# MM32F3270 register map
File version: 3.01
CPU: CM3 r2p1, selectable endian, MPU, no FPU, 3 interrupt priority bits
Registers are 32-bit, read-write, reset 0x0 unless marked. A register's access mark holds for its fields unless they carry their own. Offsets are from the block's base; [hi:lo] are bit positions; {n}, {i} and the like mark numbered series.

## Ethernet_MAC — Ethernet: media access control (MAC)
Base 0x40028000
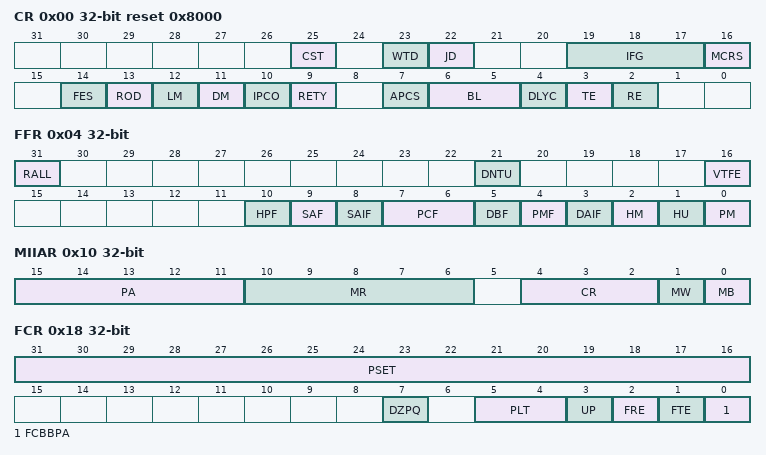
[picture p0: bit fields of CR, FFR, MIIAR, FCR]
0x00 CR reset 0x8000 — Ethernet MAC configuration register
  [25] CST — CRC stripping for Type frames
  [23] WTD — Watchdog Disable
  [22] JD — Jabber Disable
  [19:17] IFG — Inter Frame Gap
  [16] MCRS — Carrier sense disable
  [14] FES — Fast Ethernet Speed
  [13] ROD — Receive Own Disable
  [12] LM — Loopback Mode
  [11] DM — Duplex Mode
  [10] IPCO — IPv4 Checksum Offload
  [9] RETY — Retry disable
  [7] APCS — Automatic pad/CRC stripping
  [6:5] BL — Back-off limit
  [4] DLYC — Deferral check
  [3] TE — Transmitter enable
  [2] RE — Receiver enable
0x04 FFR — Ethernet MAC frame filter register
  [31] RALL — Receive All
  [21] DNTU — The MAC receiver discards all IP packets without TCP or UDP fields
  [16] VTFE — VLAN Filter Enable
  [10] HPF — Hash or Perfect Filter
  [9] SAF — Source Address Filter
  [8] SAIF — Source Address Inverse Filtering
  [7:6] PCF — Pass Control Frames
  [5] DBF — Broadcast Frames Disable
  [4] PMF — Pass All Multicast
  [3] DAIF — Destination address inverse filter-ing
  [2] HM — Hash Multicast
  [1] HU — Hash Unicast
  [0] PM — Promiscuous Mode
0x08 HTHR — Ethernet MAC hash table high register
  [31:0] HTABH — Hash Table High
0x0C HTLR — Ethernet MAC hash table low register
  [31:0] HTABL — Hash Table Low
0x10 MIIAR — Ethernet MAC MII address register
  [15:11] PA — PHY Address
  [10:6] MR — MII Register
  [4:2] CR — Clock Range
  [1] MW — MII Write
  [0] MB write-1-clears — MII Busy
0x14 MIIDR — Ethernet MAC MII data register
  [15:0] MD — MII data
0x18 FCR — Ethernet MAC flow control register
  [31:16] PSET — Pause time
  [7] DZPQ — When the flow control signal is valid, it is forbidden to generate a zero-slice pause control frame
  [5:4] PLT — Pause Low Threshold
  [3] UP — Unicast Pause Frame Detect
  [2] FRE — Receive Flow Control Enable
  [1] FTE — Transmit Flow Control Enable
  [0] FCBBPA — Flow Control Busy/Back Pressure Activate
0x1C VLANTR — Ethernet MAC VLAN tag register
  [15:0] VLANTAG — *D0
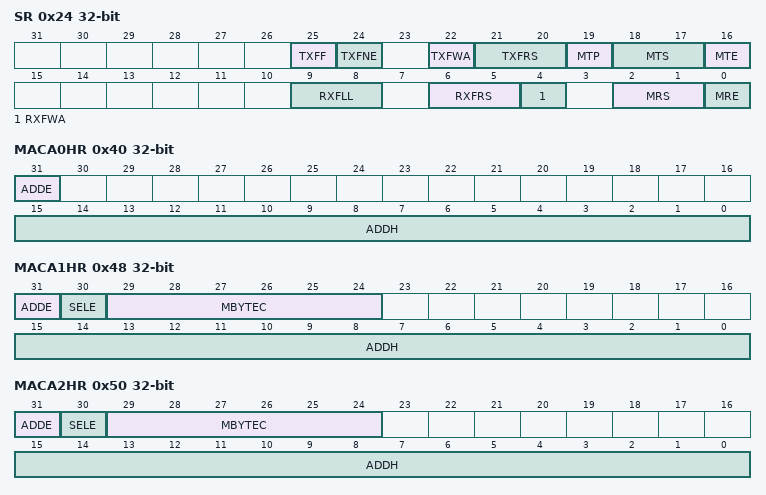
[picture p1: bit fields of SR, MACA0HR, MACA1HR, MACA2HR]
0x24 SR — Ethernet MAC VLAN tag register
  [25] TXFF — The TxFIFO is full and can no longer receive frames sent
  [24] TXFNE — The TxFIFO is not empty, there are still unsent frames
  [22] TXFWA — The TxFIFO write controller is valid and is transferring data to the TxFIFO
  [21:20] TXFRS — Write the received Tx Status or refresh the TxFIFO
  [19] MTP — The MAC transmitter is in a paused state (when in full duplex mode), and no frame transmission is scheduled
  [18:17] MTS — Transmit the input frame to be sent
  [16] MTE — The MAC MII transmission engine is actively sending data but not in an idle state
  [9:8] RXFLL — RX Fifo Full
  [6:5] RXFRS — Refresh frame data and status
  [4] RXFWA — RxFIFO write is valid, and the received frame is being transferred to RxFIFO
  [2:1] MRS — The FIFO read/write controller in the MAC receiver is working
  [0] MRE — VLAN tag identifier (for receive frames)
0x40 MACA0HR access per field — Ethernet MAC address 0 high register
  [31] ADDE ro — Always 1
  [15:0] ADDH rw — MAC address0 high [47:32]
0x44 MACA0LR — Ethernet MAC address 0 low register
  [31:0] ADDL — MAC address0 low [31:0]
0x48 MACA1HR — Ethernet MAC address 1 high register
  [31] ADDE — Address enable
  [30] SELE — Source address
  [29:24] MBYTEC — Mask Byte Control
  [15:0] ADDH — MAC address1 high [47:32]
0x4C MACA1LR — Ethernet MAC address1 low register
  [31:0] ADDL — MAC address1 low [31:0]
0x50 MACA2HR — Ethernet MAC address 2 high register
  [31] ADDE — Address e
  [30] SELE — Source address
  [29:24] MBYTEC — Mask Byte Control
  [15:0] ADDH — MAC address 2 high [47:32]
0x54 MACA2LR — Ethernet MAC address1 low register
  [31:0] ADDL — MAC address 2 low [31:0]
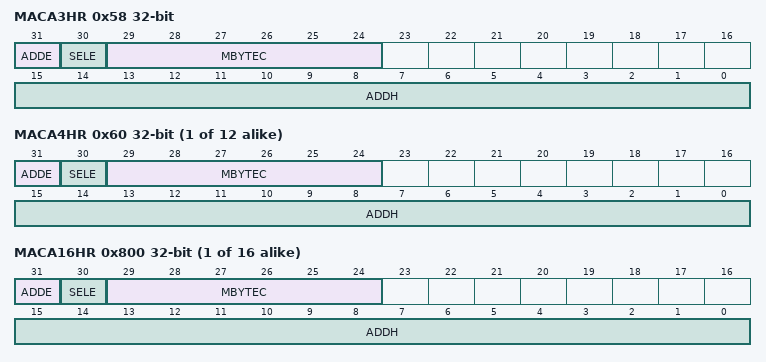
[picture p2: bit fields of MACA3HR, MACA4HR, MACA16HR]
0x58 MACA3HR — Ethernet MAC address 3 high register
  [31] ADDE — Address enable
  [30] SELE — Source address
  [29:24] MBYTEC — Mask Byte Control
  [15:0] ADDH — MAC address 3 high [47:32]
{0x44+8i} MACA{i}LR (i=3..15) — Ethernet MAC address{i} low register
  [31:0] ADDL — MAC address{i} low [31:0]
{0x40+8i} MACA{i}HR (i=4..15) — Ethernet MAC address {i} high register
  [31] ADDE — Address enable
  [30] SELE — Source address
  [29:24] MBYTEC — Mask Byte Control
  [15:0] ADDH — MAC address{i} high [47:32]
{0x780+8i} MACA{i}HR (i=16..31) — Ethernet MAC address 15 high register
  [31] ADDE — Address enable
  [30] SELE — Source address
  [29:24] MBYTEC — Mask Byte Control
  [15:0] ADDH — MAC address15 high [47:32]
{0x784+8i} MACA{i}LR (i=16..31) — Ethernet MAC address15 low register
  [31:0] ADDL — MAC address15 low [31:0]
